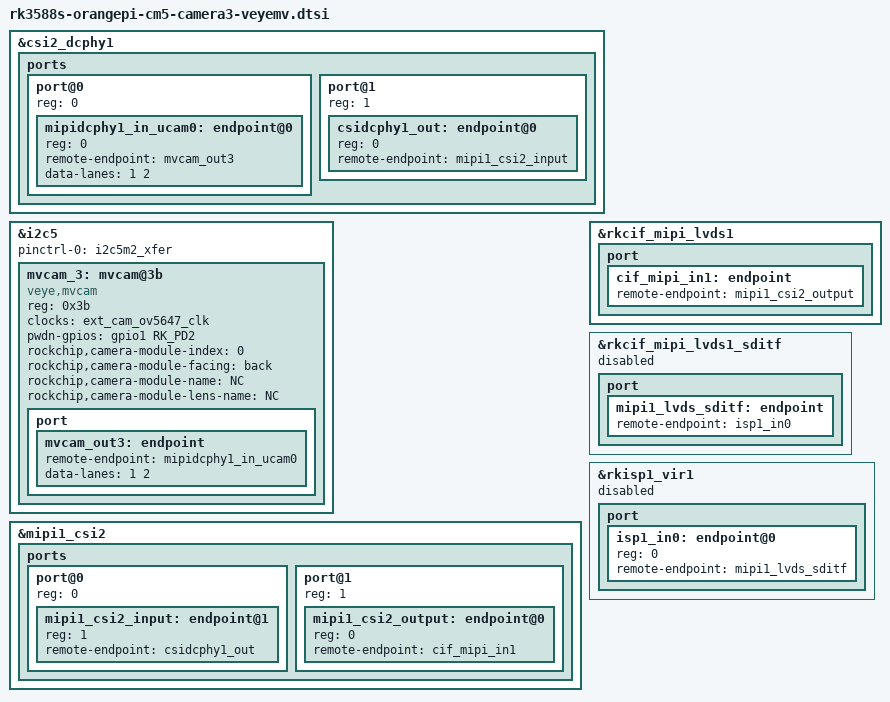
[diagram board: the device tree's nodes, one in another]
// SPDX-License-Identifier: (GPL-2.0+ OR MIT)
/*
 * Copyright (c) 2021 Rockchip Electronics Co., Ltd.
 *
 */

&csi2_dcphy1 {
	status = "okay";

	ports {
		#address-cells = <1>;
		#size-cells = <0>;

		port@0 {
			reg = <0>;
			#address-cells = <1>;
			#size-cells = <0>;

			mipidcphy1_in_ucam0: endpoint@0 {
				reg = <0>;
				remote-endpoint = <&mvcam_out3>;
				data-lanes = <1 2>;
			};

		};

		port@1 {
			reg = <1>;
			#address-cells = <1>;
			#size-cells = <0>;

			csidcphy1_out: endpoint@0 {
				reg = <0>;
				remote-endpoint = <&mipi1_csi2_input>;
			};
		};
	};
};

&i2c5 {
	status = "okay";
	pinctrl-names = "default";
	pinctrl-0 = <&i2c5m2_xfer>;
	mvcam_3: mvcam@3b{
		status = "okay";
        compatible = "veye,mvcam";
        reg = <0x3b>;
		clocks = <&ext_cam_ov5647_clk>;
		clock-names = "ext_cam_ov5647_clk";
		pwdn-gpios = <&gpio1 RK_PD2 GPIO_ACTIVE_HIGH>;
		rockchip,camera-module-index = <0>;
		rockchip,camera-module-facing = "back";
		rockchip,camera-module-name = "NC";
		rockchip,camera-module-lens-name = "NC";
		port {
			mvcam_out3: endpoint {
				remote-endpoint = <&mipidcphy1_in_ucam0>;
				data-lanes = <1 2>;
			};
		};
	};

};

&mipi1_csi2 {
	status = "okay";

	ports {
		#address-cells = <1>;
		#size-cells = <0>;

		port@0 {
			reg = <0>;
			#address-cells = <1>;
			#size-cells = <0>;

			mipi1_csi2_input: endpoint@1 {
				reg = <1>;
				remote-endpoint = <&csidcphy1_out>;
			};
		};

		port@1 {
			reg = <1>;
			#address-cells = <1>;
			#size-cells = <0>;

			mipi1_csi2_output: endpoint@0 {
				reg = <0>;
				remote-endpoint = <&cif_mipi_in1>;
			};
		};
	};
};

&rkcif_mipi_lvds1 {
	status = "okay";

	port {
		cif_mipi_in1: endpoint {
			remote-endpoint = <&mipi1_csi2_output>;
		};
	};
};

&rkcif_mipi_lvds1_sditf {
	status = "disabled";

        port {
                mipi1_lvds_sditf: endpoint {
                        remote-endpoint = <&isp1_in0>;
                };
        };
};

&rkisp1_vir1 {
	status = "disabled";

	port {
		#address-cells = <1>;
		#size-cells = <0>;

		isp1_in0: endpoint@0 {
			reg = <0>;
			remote-endpoint = <&mipi1_lvds_sditf>;
		};
	};
};
